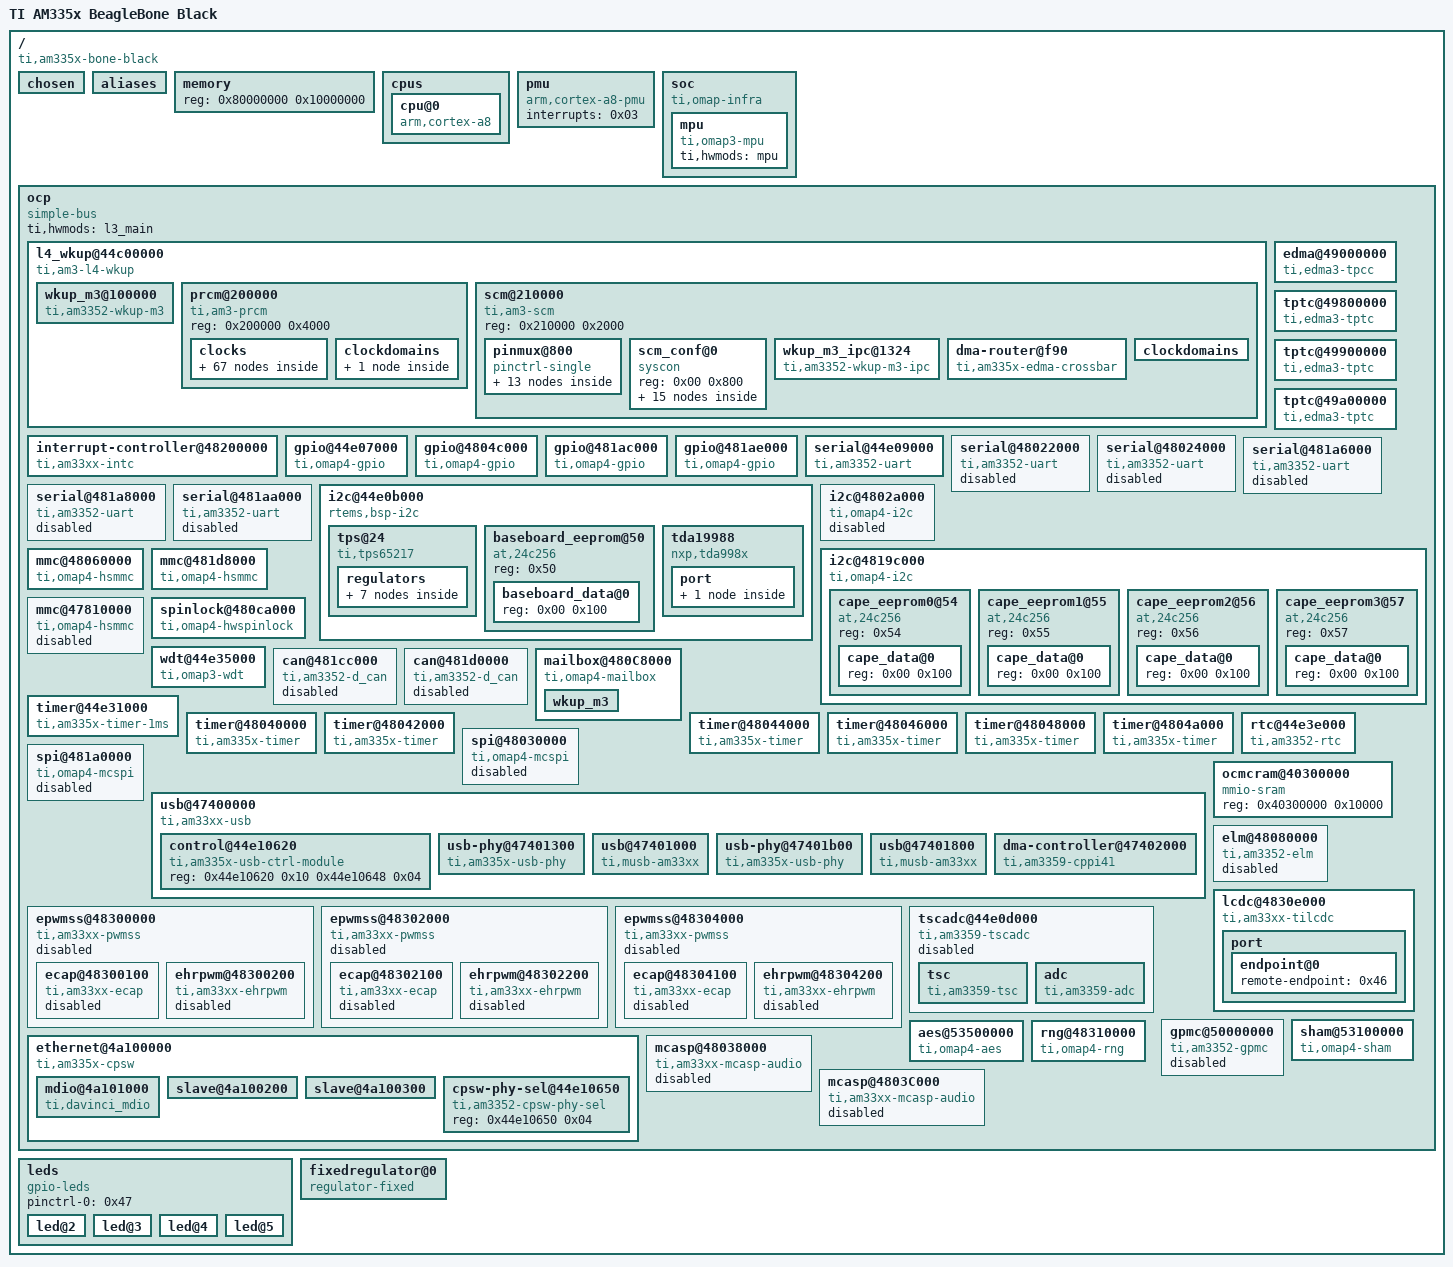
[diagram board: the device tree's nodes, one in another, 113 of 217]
/dts-v1/;

/ {
	#address-cells = < 0x01 >;
	#size-cells = < 0x01 >;
	compatible = "ti,am335x-bone-black\0ti,am335x-bone\0ti,am33xx";
	interrupt-parent = < 0x01 >;
	model = "TI AM335x BeagleBone Black";

	chosen {
	};

	aliases {
		i2c0 = "/ocp/i2c@44e0b000";
		i2c1 = "/ocp/i2c@4802a000";
		i2c2 = "/ocp/i2c@4819c000";
		serial0 = "/ocp/serial@44e09000";
		serial1 = "/ocp/serial@48022000";
		serial2 = "/ocp/serial@48024000";
		serial3 = "/ocp/serial@481a6000";
		serial4 = "/ocp/serial@481a8000";
		serial5 = "/ocp/serial@481aa000";
		d_can0 = "/ocp/can@481cc000";
		d_can1 = "/ocp/can@481d0000";
		usb0 = "/ocp/usb@47400000/usb@47401000";
		usb1 = "/ocp/usb@47400000/usb@47401800";
		phy0 = "/ocp/usb@47400000/usb-phy@47401300";
		phy1 = "/ocp/usb@47400000/usb-phy@47401b00";
		ethernet0 = "/ocp/ethernet@4a100000/slave@4a100200";
		ethernet1 = "/ocp/ethernet@4a100000/slave@4a100300";
	};

	memory {
		device_type = "memory";
		reg = < 0x80000000 0x10000000 >;
	};

	cpus {
		#address-cells = < 0x01 >;
		#size-cells = < 0x00 >;

		cpu@0 {
			compatible = "arm,cortex-a8";
			device_type = "cpu";
			reg = < 0x00 >;
			operating-points = < 0xafc80 0x139b88 0x927c0 0x12b128 0x7a120 0x112a88 0x43238 0x112a88 >;
			voltage-tolerance = < 0x02 >;
			clocks = < 0x02 >;
			clock-names = "cpu";
			clock-latency = < 0x493e0 >;
			cpu0-supply = < 0x03 >;
		};
	};

	pmu {
		compatible = "arm,cortex-a8-pmu";
		interrupts = < 0x03 >;
	};

	soc {
		compatible = "ti,omap-infra";

		mpu {
			compatible = "ti,omap3-mpu";
			ti,hwmods = "mpu";
		};
	};

	ocp {
		compatible = "simple-bus";
		#address-cells = < 0x01 >;
		#size-cells = < 0x01 >;
		ranges;
		ti,hwmods = "l3_main";

		l4_wkup@44c00000 {
			compatible = "ti,am3-l4-wkup\0simple-bus";
			#address-cells = < 0x01 >;
			#size-cells = < 0x01 >;
			ranges = < 0x00 0x44c00000 0x280000 >;
			linux,phandle = < 0x49 >;
			phandle = < 0x49 >;

			wkup_m3@100000 {
				compatible = "ti,am3352-wkup-m3";
				reg = < 0x100000 0x4000 0x180000 0x2000 >;
				reg-names = "umem\0dmem";
				ti,hwmods = "wkup_m3";
				ti,pm-firmware = "am335x-pm-firmware.elf";
				linux,phandle = < 0x26 >;
				phandle = < 0x26 >;
			};

			prcm@200000 {
				compatible = "ti,am3-prcm";
				reg = < 0x200000 0x4000 >;
				linux,phandle = < 0x4a >;
				phandle = < 0x4a >;

				clocks {
					#address-cells = < 0x01 >;
					#size-cells = < 0x00 >;
					linux,phandle = < 0x4b >;
					phandle = < 0x4b >;

					clk_32768_ck {
						#clock-cells = < 0x00 >;
						compatible = "fixed-clock";
						clock-frequency = < 0x8000 >;
						linux,phandle = < 0x14 >;
						phandle = < 0x14 >;
					};

					clk_rc32k_ck {
						#clock-cells = < 0x00 >;
						compatible = "fixed-clock";
						clock-frequency = < 0x7d00 >;
						linux,phandle = < 0x13 >;
						phandle = < 0x13 >;
					};

					virt_19200000_ck {
						#clock-cells = < 0x00 >;
						compatible = "fixed-clock";
						clock-frequency = < 0x124f800 >;
						linux,phandle = < 0x21 >;
						phandle = < 0x21 >;
					};

					virt_24000000_ck {
						#clock-cells = < 0x00 >;
						compatible = "fixed-clock";
						clock-frequency = < 0x16e3600 >;
						linux,phandle = < 0x22 >;
						phandle = < 0x22 >;
					};

					virt_25000000_ck {
						#clock-cells = < 0x00 >;
						compatible = "fixed-clock";
						clock-frequency = < 0x17d7840 >;
						linux,phandle = < 0x23 >;
						phandle = < 0x23 >;
					};

					virt_26000000_ck {
						#clock-cells = < 0x00 >;
						compatible = "fixed-clock";
						clock-frequency = < 0x18cba80 >;
						linux,phandle = < 0x24 >;
						phandle = < 0x24 >;
					};

					tclkin_ck {
						#clock-cells = < 0x00 >;
						compatible = "fixed-clock";
						clock-frequency = < 0xb71b00 >;
						linux,phandle = < 0x12 >;
						phandle = < 0x12 >;
					};

					dpll_core_ck {
						#clock-cells = < 0x00 >;
						compatible = "ti,am3-dpll-core-clock";
						clocks = < 0x04 0x04 >;
						reg = < 0x490 0x45c 0x468 >;
						linux,phandle = < 0x05 >;
						phandle = < 0x05 >;
					};

					dpll_core_x2_ck {
						#clock-cells = < 0x00 >;
						compatible = "ti,am3-dpll-x2-clock";
						clocks = < 0x05 >;
						linux,phandle = < 0x06 >;
						phandle = < 0x06 >;
					};

					dpll_core_m4_ck {
						#clock-cells = < 0x00 >;
						compatible = "ti,divider-clock";
						clocks = < 0x06 >;
						ti,max-div = < 0x1f >;
						reg = < 0x480 >;
						ti,index-starts-at-one;
						linux,phandle = < 0x0e >;
						phandle = < 0x0e >;
					};

					dpll_core_m5_ck {
						#clock-cells = < 0x00 >;
						compatible = "ti,divider-clock";
						clocks = < 0x06 >;
						ti,max-div = < 0x1f >;
						reg = < 0x484 >;
						ti,index-starts-at-one;
						linux,phandle = < 0x16 >;
						phandle = < 0x16 >;
					};

					dpll_core_m6_ck {
						#clock-cells = < 0x00 >;
						compatible = "ti,divider-clock";
						clocks = < 0x06 >;
						ti,max-div = < 0x1f >;
						reg = < 0x4d8 >;
						ti,index-starts-at-one;
						linux,phandle = < 0x4c >;
						phandle = < 0x4c >;
					};

					dpll_mpu_ck {
						#clock-cells = < 0x00 >;
						compatible = "ti,am3-dpll-clock";
						clocks = < 0x04 0x04 >;
						reg = < 0x488 0x420 0x42c >;
						linux,phandle = < 0x02 >;
						phandle = < 0x02 >;
					};

					dpll_mpu_m2_ck {
						#clock-cells = < 0x00 >;
						compatible = "ti,divider-clock";
						clocks = < 0x02 >;
						ti,max-div = < 0x1f >;
						reg = < 0x4a8 >;
						ti,index-starts-at-one;
						linux,phandle = < 0x4d >;
						phandle = < 0x4d >;
					};

					dpll_ddr_ck {
						#clock-cells = < 0x00 >;
						compatible = "ti,am3-dpll-no-gate-clock";
						clocks = < 0x04 0x04 >;
						reg = < 0x494 0x434 0x440 >;
						linux,phandle = < 0x07 >;
						phandle = < 0x07 >;
					};

					dpll_ddr_m2_ck {
						#clock-cells = < 0x00 >;
						compatible = "ti,divider-clock";
						clocks = < 0x07 >;
						ti,max-div = < 0x1f >;
						reg = < 0x4a0 >;
						ti,index-starts-at-one;
						linux,phandle = < 0x08 >;
						phandle = < 0x08 >;
					};

					dpll_ddr_m2_div2_ck {
						#clock-cells = < 0x00 >;
						compatible = "fixed-factor-clock";
						clocks = < 0x08 >;
						clock-mult = < 0x01 >;
						clock-div = < 0x02 >;
						linux,phandle = < 0x4e >;
						phandle = < 0x4e >;
					};

					dpll_disp_ck {
						#clock-cells = < 0x00 >;
						compatible = "ti,am3-dpll-no-gate-clock";
						clocks = < 0x04 0x04 >;
						reg = < 0x498 0x448 0x454 >;
						linux,phandle = < 0x09 >;
						phandle = < 0x09 >;
					};

					dpll_disp_m2_ck {
						#clock-cells = < 0x00 >;
						compatible = "ti,divider-clock";
						clocks = < 0x09 >;
						ti,max-div = < 0x1f >;
						reg = < 0x4a4 >;
						ti,index-starts-at-one;
						ti,set-rate-parent;
						linux,phandle = < 0x10 >;
						phandle = < 0x10 >;
					};

					dpll_per_ck {
						#clock-cells = < 0x00 >;
						compatible = "ti,am3-dpll-no-gate-j-type-clock";
						clocks = < 0x04 0x04 >;
						reg = < 0x48c 0x470 0x49c >;
						linux,phandle = < 0x0a >;
						phandle = < 0x0a >;
					};

					dpll_per_m2_ck {
						#clock-cells = < 0x00 >;
						compatible = "ti,divider-clock";
						clocks = < 0x0a >;
						ti,max-div = < 0x1f >;
						reg = < 0x4ac >;
						ti,index-starts-at-one;
						linux,phandle = < 0x0b >;
						phandle = < 0x0b >;
					};

					dpll_per_m2_div4_wkupdm_ck {
						#clock-cells = < 0x00 >;
						compatible = "fixed-factor-clock";
						clocks = < 0x0b >;
						clock-mult = < 0x01 >;
						clock-div = < 0x04 >;
						linux,phandle = < 0x4f >;
						phandle = < 0x4f >;
					};

					dpll_per_m2_div4_ck {
						#clock-cells = < 0x00 >;
						compatible = "fixed-factor-clock";
						clocks = < 0x0b >;
						clock-mult = < 0x01 >;
						clock-div = < 0x04 >;
						linux,phandle = < 0x50 >;
						phandle = < 0x50 >;
					};

					cefuse_fck {
						#clock-cells = < 0x00 >;
						compatible = "ti,gate-clock";
						clocks = < 0x04 >;
						ti,bit-shift = < 0x01 >;
						reg = < 0xa20 >;
						linux,phandle = < 0x51 >;
						phandle = < 0x51 >;
					};

					clk_24mhz {
						#clock-cells = < 0x00 >;
						compatible = "fixed-factor-clock";
						clocks = < 0x0b >;
						clock-mult = < 0x01 >;
						clock-div = < 0x08 >;
						linux,phandle = < 0x0c >;
						phandle = < 0x0c >;
					};

					clkdiv32k_ck {
						#clock-cells = < 0x00 >;
						compatible = "fixed-factor-clock";
						clocks = < 0x0c >;
						clock-mult = < 0x01 >;
						clock-div = < 0x2dc >;
						linux,phandle = < 0x0d >;
						phandle = < 0x0d >;
					};

					clkdiv32k_ick {
						#clock-cells = < 0x00 >;
						compatible = "ti,gate-clock";
						clocks = < 0x0d >;
						ti,bit-shift = < 0x01 >;
						reg = < 0x14c >;
						linux,phandle = < 0x11 >;
						phandle = < 0x11 >;
					};

					l3_gclk {
						#clock-cells = < 0x00 >;
						compatible = "fixed-factor-clock";
						clocks = < 0x0e >;
						clock-mult = < 0x01 >;
						clock-div = < 0x01 >;
						linux,phandle = < 0x0f >;
						phandle = < 0x0f >;
					};

					pruss_ocp_gclk {
						#clock-cells = < 0x00 >;
						compatible = "ti,mux-clock";
						clocks = < 0x0f 0x10 >;
						reg = < 0x530 >;
						linux,phandle = < 0x52 >;
						phandle = < 0x52 >;
					};

					mmu_fck {
						#clock-cells = < 0x00 >;
						compatible = "ti,gate-clock";
						clocks = < 0x0e >;
						ti,bit-shift = < 0x01 >;
						reg = < 0x914 >;
						linux,phandle = < 0x53 >;
						phandle = < 0x53 >;
					};

					timer1_fck {
						#clock-cells = < 0x00 >;
						compatible = "ti,mux-clock";
						clocks = < 0x04 0x11 0x12 0x13 0x14 >;
						reg = < 0x528 >;
						linux,phandle = < 0x54 >;
						phandle = < 0x54 >;
					};

					timer2_fck {
						#clock-cells = < 0x00 >;
						compatible = "ti,mux-clock";
						clocks = < 0x12 0x04 0x11 >;
						reg = < 0x508 >;
						linux,phandle = < 0x55 >;
						phandle = < 0x55 >;
					};

					timer3_fck {
						#clock-cells = < 0x00 >;
						compatible = "ti,mux-clock";
						clocks = < 0x12 0x04 0x11 >;
						reg = < 0x50c >;
						linux,phandle = < 0x56 >;
						phandle = < 0x56 >;
					};

					timer4_fck {
						#clock-cells = < 0x00 >;
						compatible = "ti,mux-clock";
						clocks = < 0x12 0x04 0x11 >;
						reg = < 0x510 >;
						linux,phandle = < 0x57 >;
						phandle = < 0x57 >;
					};

					timer5_fck {
						#clock-cells = < 0x00 >;
						compatible = "ti,mux-clock";
						clocks = < 0x12 0x04 0x11 >;
						reg = < 0x518 >;
						linux,phandle = < 0x58 >;
						phandle = < 0x58 >;
					};

					timer6_fck {
						#clock-cells = < 0x00 >;
						compatible = "ti,mux-clock";
						clocks = < 0x12 0x04 0x11 >;
						reg = < 0x51c >;
						linux,phandle = < 0x59 >;
						phandle = < 0x59 >;
					};

					timer7_fck {
						#clock-cells = < 0x00 >;
						compatible = "ti,mux-clock";
						clocks = < 0x12 0x04 0x11 >;
						reg = < 0x504 >;
						linux,phandle = < 0x5a >;
						phandle = < 0x5a >;
					};

					usbotg_fck {
						#clock-cells = < 0x00 >;
						compatible = "ti,gate-clock";
						clocks = < 0x0a >;
						ti,bit-shift = < 0x08 >;
						reg = < 0x47c >;
						linux,phandle = < 0x5b >;
						phandle = < 0x5b >;
					};

					dpll_core_m4_div2_ck {
						#clock-cells = < 0x00 >;
						compatible = "fixed-factor-clock";
						clocks = < 0x0e >;
						clock-mult = < 0x01 >;
						clock-div = < 0x02 >;
						linux,phandle = < 0x15 >;
						phandle = < 0x15 >;
					};

					ieee5000_fck {
						#clock-cells = < 0x00 >;
						compatible = "ti,gate-clock";
						clocks = < 0x15 >;
						ti,bit-shift = < 0x01 >;
						reg = < 0xe4 >;
						linux,phandle = < 0x5c >;
						phandle = < 0x5c >;
					};

					wdt1_fck {
						#clock-cells = < 0x00 >;
						compatible = "ti,mux-clock";
						clocks = < 0x13 0x11 >;
						reg = < 0x538 >;
						linux,phandle = < 0x5d >;
						phandle = < 0x5d >;
					};

					l4_rtc_gclk {
						#clock-cells = < 0x00 >;
						compatible = "fixed-factor-clock";
						clocks = < 0x0e >;
						clock-mult = < 0x01 >;
						clock-div = < 0x02 >;
						linux,phandle = < 0x5e >;
						phandle = < 0x5e >;
					};

					l4hs_gclk {
						#clock-cells = < 0x00 >;
						compatible = "fixed-factor-clock";
						clocks = < 0x0e >;
						clock-mult = < 0x01 >;
						clock-div = < 0x01 >;
						linux,phandle = < 0x5f >;
						phandle = < 0x5f >;
					};

					l3s_gclk {
						#clock-cells = < 0x00 >;
						compatible = "fixed-factor-clock";
						clocks = < 0x15 >;
						clock-mult = < 0x01 >;
						clock-div = < 0x01 >;
						linux,phandle = < 0x60 >;
						phandle = < 0x60 >;
					};

					l4fw_gclk {
						#clock-cells = < 0x00 >;
						compatible = "fixed-factor-clock";
						clocks = < 0x15 >;
						clock-mult = < 0x01 >;
						clock-div = < 0x01 >;
						linux,phandle = < 0x61 >;
						phandle = < 0x61 >;
					};

					l4ls_gclk {
						#clock-cells = < 0x00 >;
						compatible = "fixed-factor-clock";
						clocks = < 0x15 >;
						clock-mult = < 0x01 >;
						clock-div = < 0x01 >;
						linux,phandle = < 0x25 >;
						phandle = < 0x25 >;
					};

					sysclk_div_ck {
						#clock-cells = < 0x00 >;
						compatible = "fixed-factor-clock";
						clocks = < 0x0e >;
						clock-mult = < 0x01 >;
						clock-div = < 0x01 >;
						linux,phandle = < 0x62 >;
						phandle = < 0x62 >;
					};

					cpsw_125mhz_gclk {
						#clock-cells = < 0x00 >;
						compatible = "fixed-factor-clock";
						clocks = < 0x16 >;
						clock-mult = < 0x01 >;
						clock-div = < 0x02 >;
						linux,phandle = < 0x3f >;
						phandle = < 0x3f >;
					};

					cpsw_cpts_rft_clk {
						#clock-cells = < 0x00 >;
						compatible = "ti,mux-clock";
						clocks = < 0x16 0x0e >;
						reg = < 0x520 >;
						linux,phandle = < 0x40 >;
						phandle = < 0x40 >;
					};

					gpio0_dbclk_mux_ck {
						#clock-cells = < 0x00 >;
						compatible = "ti,mux-clock";
						clocks = < 0x13 0x14 0x11 >;
						reg = < 0x53c >;
						linux,phandle = < 0x17 >;
						phandle = < 0x17 >;
					};

					gpio0_dbclk {
						#clock-cells = < 0x00 >;
						compatible = "ti,gate-clock";
						clocks = < 0x17 >;
						ti,bit-shift = < 0x12 >;
						reg = < 0x408 >;
						linux,phandle = < 0x63 >;
						phandle = < 0x63 >;
					};

					gpio1_dbclk {
						#clock-cells = < 0x00 >;
						compatible = "ti,gate-clock";
						clocks = < 0x11 >;
						ti,bit-shift = < 0x12 >;
						reg = < 0xac >;
						linux,phandle = < 0x64 >;
						phandle = < 0x64 >;
					};

					gpio2_dbclk {
						#clock-cells = < 0x00 >;
						compatible = "ti,gate-clock";
						clocks = < 0x11 >;
						ti,bit-shift = < 0x12 >;
						reg = < 0xb0 >;
						linux,phandle = < 0x65 >;
						phandle = < 0x65 >;
					};

					gpio3_dbclk {
						#clock-cells = < 0x00 >;
						compatible = "ti,gate-clock";
						clocks = < 0x11 >;
						ti,bit-shift = < 0x12 >;
						reg = < 0xb4 >;
						linux,phandle = < 0x66 >;
						phandle = < 0x66 >;
					};

					lcd_gclk {
						#clock-cells = < 0x00 >;
						compatible = "ti,mux-clock";
						clocks = < 0x10 0x16 0x0b >;
						reg = < 0x534 >;
						ti,set-rate-parent;
						linux,phandle = < 0x19 >;
						phandle = < 0x19 >;
					};

					mmc_clk {
						#clock-cells = < 0x00 >;
						compatible = "fixed-factor-clock";
						clocks = < 0x0b >;
						clock-mult = < 0x01 >;
						clock-div = < 0x02 >;
						linux,phandle = < 0x67 >;
						phandle = < 0x67 >;
					};

					gfx_fclk_clksel_ck {
						#clock-cells = < 0x00 >;
						compatible = "ti,mux-clock";
						clocks = < 0x0e 0x0b >;
						ti,bit-shift = < 0x01 >;
						reg = < 0x52c >;
						linux,phandle = < 0x18 >;
						phandle = < 0x18 >;
					};

					gfx_fck_div_ck {
						#clock-cells = < 0x00 >;
						compatible = "ti,divider-clock";
						clocks = < 0x18 >;
						reg = < 0x52c >;
						ti,max-div = < 0x02 >;
						linux,phandle = < 0x68 >;
						phandle = < 0x68 >;
					};

					sysclkout_pre_ck {
						#clock-cells = < 0x00 >;
						compatible = "ti,mux-clock";
						clocks = < 0x14 0x0f 0x08 0x0b 0x19 >;
						reg = < 0x700 >;
						linux,phandle = < 0x1a >;
						phandle = < 0x1a >;
					};

					clkout2_div_ck {
						#clock-cells = < 0x00 >;
						compatible = "ti,divider-clock";
						clocks = < 0x1a >;
						ti,bit-shift = < 0x03 >;
						ti,max-div = < 0x08 >;
						reg = < 0x700 >;
						linux,phandle = < 0x1f >;
						phandle = < 0x1f >;
					};

					dbg_sysclk_ck {
						#clock-cells = < 0x00 >;
						compatible = "ti,gate-clock";
						clocks = < 0x04 >;
						ti,bit-shift = < 0x13 >;
						reg = < 0x414 >;
						linux,phandle = < 0x1b >;
						phandle = < 0x1b >;
					};

					dbg_clka_ck {
						#clock-cells = < 0x00 >;
						compatible = "ti,gate-clock";
						clocks = < 0x0e >;
						ti,bit-shift = < 0x1e >;
						reg = < 0x414 >;
						linux,phandle = < 0x1c >;
						phandle = < 0x1c >;
					};

					stm_pmd_clock_mux_ck {
						#clock-cells = < 0x00 >;
						compatible = "ti,mux-clock";
						clocks = < 0x1b 0x1c >;
						ti,bit-shift = < 0x16 >;
						reg = < 0x414 >;
						linux,phandle = < 0x1d >;
						phandle = < 0x1d >;
					};

					trace_pmd_clk_mux_ck {
						#clock-cells = < 0x00 >;
						compatible = "ti,mux-clock";
						clocks = < 0x1b 0x1c >;
						ti,bit-shift = < 0x14 >;
						reg = < 0x414 >;
						linux,phandle = < 0x1e >;
						phandle = < 0x1e >;
					};

					stm_clk_div_ck {
						#clock-cells = < 0x00 >;
						compatible = "ti,divider-clock";
						clocks = < 0x1d >;
						ti,bit-shift = < 0x1b >;
						ti,max-div = < 0x40 >;
						reg = < 0x414 >;
						ti,index-power-of-two;
						linux,phandle = < 0x69 >;
						phandle = < 0x69 >;
					};

					trace_clk_div_ck {
						#clock-cells = < 0x00 >;
						compatible = "ti,divider-clock";
						clocks = < 0x1e >;
						ti,bit-shift = < 0x18 >;
						ti,max-div = < 0x40 >;
						reg = < 0x414 >;
						ti,index-power-of-two;
						linux,phandle = < 0x6a >;
						phandle = < 0x6a >;
					};

					clkout2_ck {
						#clock-cells = < 0x00 >;
						compatible = "ti,gate-clock";
						clocks = < 0x1f >;
						ti,bit-shift = < 0x07 >;
						reg = < 0x700 >;
						linux,phandle = < 0x6b >;
						phandle = < 0x6b >;
					};
				};

				clockdomains {
					linux,phandle = < 0x6c >;
					phandle = < 0x6c >;

					clk_24mhz_clkdm {
						compatible = "ti,clockdomain";
						clocks = < 0x11 >;
						linux,phandle = < 0x6d >;
						phandle = < 0x6d >;
					};
				};
			};

			scm@210000 {
				compatible = "ti,am3-scm\0simple-bus";
				reg = < 0x210000 0x2000 >;
				#address-cells = < 0x01 >;
				#size-cells = < 0x01 >;
				ranges = < 0x00 0x210000 0x2000 >;
				linux,phandle = < 0x6e >;
				phandle = < 0x6e >;

				pinmux@800 {
					compatible = "pinctrl-single";
					reg = < 0x800 0x238 >;
					#address-cells = < 0x01 >;
					#size-cells = < 0x00 >;
					pinctrl-single,register-width = < 0x20 >;
					pinctrl-single,function-mask = < 0x7f >;
					pinctrl-names = "default";
					pinctrl-0 = < 0x20 >;
					linux,phandle = < 0x6f >;
					phandle = < 0x6f >;

					user_leds_s0 {
						pinctrl-single,pins = < 0x54 0x07 0x58 0x17 0x5c 0x07 0x60 0x17 >;
						linux,phandle = < 0x47 >;
						phandle = < 0x47 >;
					};

					pinmux_i2c0_pins {
						pinctrl-single,pins = < 0x188 0x30 0x18c 0x30 >;
						linux,phandle = < 0x2e >;
						phandle = < 0x2e >;
					};

					pinmux_i2c2_pins {
						pinctrl-single,pins = < 0x178 0x33 0x17c 0x33 >;
						linux,phandle = < 0x32 >;
						phandle = < 0x32 >;
					};

					pinmux_uart0_pins {
						pinctrl-single,pins = < 0x170 0x30 0x174 0x00 >;
						linux,phandle = < 0x2d >;
						phandle = < 0x2d >;
					};

					pinmux_clkout2_pin {
						pinctrl-single,pins = < 0x1b4 0x03 >;
						linux,phandle = < 0x20 >;
						phandle = < 0x20 >;
					};

					cpsw_default {
						pinctrl-single,pins = < 0x110 0x30 0x114 0x00 0x118 0x30 0x11c 0x00 0x120 0x00 0x124 0x00 0x128 0x00 0x12c 0x30 0x130 0x30 0x134 0x30 0x138 0x30 0x13c 0x30 0x140 0x30 >;
						linux,phandle = < 0x41 >;
						phandle = < 0x41 >;
					};

					cpsw_sleep {
						pinctrl-single,pins = < 0x110 0x27 0x114 0x27 0x118 0x27 0x11c 0x27 0x120 0x27 0x124 0x27 0x128 0x27 0x12c 0x27 0x130 0x27 0x134 0x27 0x138 0x27 0x13c 0x27 0x140 0x27 >;
						linux,phandle = < 0x42 >;
						phandle = < 0x42 >;
					};

					davinci_mdio_default {
						pinctrl-single,pins = < 0x148 0x30 0x14c 0x10 >;
						linux,phandle = < 0x43 >;
						phandle = < 0x43 >;
					};

					davinci_mdio_sleep {
						pinctrl-single,pins = < 0x148 0x27 0x14c 0x27 >;
						linux,phandle = < 0x44 >;
						phandle = < 0x44 >;
					};

					pinmux_mmc1_pins {
						pinctrl-single,pins = < 0x160 0x2f >;
						linux,phandle = < 0x34 >;
						phandle = < 0x34 >;
					};

					pinmux_emmc_pins {
						pinctrl-single,pins = < 0x80 0x32 0x84 0x32 0x00 0x31 0x04 0x31 0x08 0x31 0x0c 0x31 0x10 0x31 0x14 0x31 0x18 0x31 0x1c 0x31 >;
						linux,phandle = < 0x37 >;
						phandle = < 0x37 >;
					};

					nxp_hdmi_bonelt_pins {
						pinctrl-single,pins = < 0x1b0 0x03 0xa0 0x08 0xa4 0x08 0xa8 0x08 0xac 0x08 0xb0 0x08 0xb4 0x08 0xb8 0x08 0xbc 0x08 0xc0 0x08 0xc4 0x08 0xc8 0x08 0xcc 0x08 0xd0 0x08 0xd4 0x08 0xd8 0x08 0xdc 0x08 0xe0 0x00 0xe4 0x00 0xe8 0x00 0xec 0x00 >;
						linux,phandle = < 0x2f >;
						phandle = < 0x2f >;
					};

					nxp_hdmi_bonelt_off_pins {
						pinctrl-single,pins = < 0x1b0 0x03 >;
						linux,phandle = < 0x30 >;
						phandle = < 0x30 >;
					};
				};

				scm_conf@0 {
					compatible = "syscon";
					reg = < 0x00 0x800 >;
					#address-cells = < 0x01 >;
					#size-cells = < 0x01 >;
					linux,phandle = < 0x39 >;
					phandle = < 0x39 >;

					clocks {
						#address-cells = < 0x01 >;
						#size-cells = < 0x00 >;
						linux,phandle = < 0x70 >;
						phandle = < 0x70 >;

						sys_clkin_ck {
							#clock-cells = < 0x00 >;
							compatible = "ti,mux-clock";
							clocks = < 0x21 0x22 0x23 0x24 >;
							ti,bit-shift = < 0x16 >;
							reg = < 0x40 >;
							linux,phandle = < 0x04 >;
							phandle = < 0x04 >;
						};

						adc_tsc_fck {
							#clock-cells = < 0x00 >;
							compatible = "fixed-factor-clock";
							clocks = < 0x04 >;
							clock-mult = < 0x01 >;
							clock-div = < 0x01 >;
							linux,phandle = < 0x71 >;
							phandle = < 0x71 >;
						};

						dcan0_fck {
							#clock-cells = < 0x00 >;
							compatible = "fixed-factor-clock";
							clocks = < 0x04 >;
							clock-mult = < 0x01 >;
							clock-div = < 0x01 >;
							linux,phandle = < 0x38 >;
							phandle = < 0x38 >;
						};

						dcan1_fck {
							#clock-cells = < 0x00 >;
							compatible = "fixed-factor-clock";
							clocks = < 0x04 >;
							clock-mult = < 0x01 >;
							clock-div = < 0x01 >;
							linux,phandle = < 0x3a >;
							phandle = < 0x3a >;
						};

						mcasp0_fck {
							#clock-cells = < 0x00 >;
							compatible = "fixed-factor-clock";
							clocks = < 0x04 >;
							clock-mult = < 0x01 >;
							clock-div = < 0x01 >;
							linux,phandle = < 0x72 >;
							phandle = < 0x72 >;
						};

						mcasp1_fck {
							#clock-cells = < 0x00 >;
							compatible = "fixed-factor-clock";
							clocks = < 0x04 >;
							clock-mult = < 0x01 >;
							clock-div = < 0x01 >;
							linux,phandle = < 0x73 >;
							phandle = < 0x73 >;
						};

						smartreflex0_fck {
							#clock-cells = < 0x00 >;
							compatible = "fixed-factor-clock";
							clocks = < 0x04 >;
							clock-mult = < 0x01 >;
							clock-div = < 0x01 >;
							linux,phandle = < 0x74 >;
							phandle = < 0x74 >;
						};

						smartreflex1_fck {
							#clock-cells = < 0x00 >;
							compatible = "fixed-factor-clock";
							clocks = < 0x04 >;
							clock-mult = < 0x01 >;
							clock-div = < 0x01 >;
							linux,phandle = < 0x75 >;
							phandle = < 0x75 >;
						};

						sha0_fck {
							#clock-cells = < 0x00 >;
							compatible = "fixed-factor-clock";
							clocks = < 0x04 >;
							clock-mult = < 0x01 >;
							clock-div = < 0x01 >;
							linux,phandle = < 0x76 >;
							phandle = < 0x76 >;
						};

						aes0_fck {
							#clock-cells = < 0x00 >;
							compatible = "fixed-factor-clock";
							clocks = < 0x04 >;
							clock-mult = < 0x01 >;
							clock-div = < 0x01 >;
							linux,phandle = < 0x77 >;
							phandle = < 0x77 >;
						};

						rng_fck {
							#clock-cells = < 0x00 >;
							compatible = "fixed-factor-clock";
							clocks = < 0x04 >;
							clock-mult = < 0x01 >;
							clock-div = < 0x01 >;
							linux,phandle = < 0x78 >;
							phandle = < 0x78 >;
						};

						ehrpwm0_tbclk@44e10664 {
							#clock-cells = < 0x00 >;
							compatible = "ti,gate-clock";
							clocks = < 0x25 >;
							ti,bit-shift = < 0x00 >;
							reg = < 0x664 >;
							linux,phandle = < 0x79 >;
							phandle = < 0x79 >;
						};

						ehrpwm1_tbclk@44e10664 {
							#clock-cells = < 0x00 >;
							compatible = "ti,gate-clock";
							clocks = < 0x25 >;
							ti,bit-shift = < 0x01 >;
							reg = < 0x664 >;
							linux,phandle = < 0x7a >;
							phandle = < 0x7a >;
						};

						ehrpwm2_tbclk@44e10664 {
							#clock-cells = < 0x00 >;
							compatible = "ti,gate-clock";
							clocks = < 0x25 >;
							ti,bit-shift = < 0x02 >;
							reg = < 0x664 >;
							linux,phandle = < 0x7b >;
							phandle = < 0x7b >;
						};
					};
				};

				wkup_m3_ipc@1324 {
					compatible = "ti,am3352-wkup-m3-ipc";
					reg = < 0x1324 0x24 >;
					interrupts = < 0x4e >;
					ti,rproc = < 0x26 >;
					mboxes = < 0x27 0x28 >;
					linux,phandle = < 0x7c >;
					phandle = < 0x7c >;
				};

				dma-router@f90 {
					compatible = "ti,am335x-edma-crossbar";
					reg = < 0xf90 0x40 >;
					#dma-cells = < 0x03 >;
					dma-requests = < 0x20 >;
					dma-masters = < 0x29 >;
					linux,phandle = < 0x33 >;
					phandle = < 0x33 >;
				};

				clockdomains {
					linux,phandle = < 0x7d >;
					phandle = < 0x7d >;
				};
			};
		};

		interrupt-controller@48200000 {
			compatible = "ti,am33xx-intc";
			interrupt-controller;
			#interrupt-cells = < 0x01 >;
			reg = < 0x48200000 0x1000 >;
			linux,phandle = < 0x01 >;
			phandle = < 0x01 >;
		};

		edma@49000000 {
			compatible = "ti,edma3-tpcc";
			ti,hwmods = "tpcc";
			reg = < 0x49000000 0x10000 >;
			reg-names = "edma3_cc";
			interrupts = < 0x0c 0x0d 0x0e >;
			interrupt-names = "edma3_ccint\0emda3_mperr\0edma3_ccerrint";
			dma-requests = < 0x40 >;
			#dma-cells = < 0x02 >;
			ti,tptcs = < 0x2a 0x07 0x2b 0x05 0x2c 0x00 >;
			ti,edma-memcpy-channels = < 0x14 0x15 >;
			linux,phandle = < 0x29 >;
			phandle = < 0x29 >;
		};

		tptc@49800000 {
			compatible = "ti,edma3-tptc";
			ti,hwmods = "tptc0";
			reg = < 0x49800000 0x100000 >;
			interrupts = < 0x70 >;
			interrupt-names = "edma3_tcerrint";
			linux,phandle = < 0x2a >;
			phandle = < 0x2a >;
		};

		tptc@49900000 {
			compatible = "ti,edma3-tptc";
			ti,hwmods = "tptc1";
			reg = < 0x49900000 0x100000 >;
			interrupts = < 0x71 >;
			interrupt-names = "edma3_tcerrint";
			linux,phandle = < 0x2b >;
			phandle = < 0x2b >;
		};

		tptc@49a00000 {
			compatible = "ti,edma3-tptc";
			ti,hwmods = "tptc2";
			reg = < 0x49a00000 0x100000 >;
			interrupts = < 0x72 >;
			interrupt-names = "edma3_tcerrint";
			linux,phandle = < 0x2c >;
			phandle = < 0x2c >;
		};

		gpio@44e07000 {
			compatible = "ti,omap4-gpio";
			ti,hwmods = "gpio1";
			gpio-controller;
			#gpio-cells = < 0x02 >;
			interrupt-controller;
			#interrupt-cells = < 0x02 >;
			reg = < 0x44e07000 0x1000 >;
			interrupts = < 0x60 >;
			linux,phandle = < 0x35 >;
			phandle = < 0x35 >;
		};

		gpio@4804c000 {
			compatible = "ti,omap4-gpio";
			ti,hwmods = "gpio2";
			gpio-controller;
			#gpio-cells = < 0x02 >;
			interrupt-controller;
			#interrupt-cells = < 0x02 >;
			reg = < 0x4804c000 0x1000 >;
			interrupts = < 0x62 >;
			linux,phandle = < 0x48 >;
			phandle = < 0x48 >;
		};

		gpio@481ac000 {
			compatible = "ti,omap4-gpio";
			ti,hwmods = "gpio3";
			gpio-controller;
			#gpio-cells = < 0x02 >;
			interrupt-controller;
			#interrupt-cells = < 0x02 >;
			reg = < 0x481ac000 0x1000 >;
			interrupts = < 0x20 >;
			linux,phandle = < 0x7e >;
			phandle = < 0x7e >;
		};

		gpio@481ae000 {
			compatible = "ti,omap4-gpio";
			ti,hwmods = "gpio4";
			gpio-controller;
			#gpio-cells = < 0x02 >;
			interrupt-controller;
			#interrupt-cells = < 0x02 >;
			reg = < 0x481ae000 0x1000 >;
			interrupts = < 0x3e >;
			linux,phandle = < 0x7f >;
			phandle = < 0x7f >;
		};

		serial@44e09000 {
			compatible = "ti,am3352-uart\0ti,omap3-uart";
			ti,hwmods = "uart1";
			clock-frequency = < 0x2dc6c00 >;
			reg = < 0x44e09000 0x2000 >;
			interrupts = < 0x48 >;
			status = "okay";
			dmas = < 0x29 0x1a 0x00 0x29 0x1b 0x00 >;
			dma-names = "tx\0rx";
			pinctrl-names = "default";
			pinctrl-0 = < 0x2d >;
			linux,phandle = < 0x80 >;
			phandle = < 0x80 >;
		};

		serial@48022000 {
			compatible = "ti,am3352-uart\0ti,omap3-uart";
			ti,hwmods = "uart2";
			clock-frequency = < 0x2dc6c00 >;
			reg = < 0x48022000 0x2000 >;
			interrupts = < 0x49 >;
			status = "disabled";
			dmas = < 0x29 0x1c 0x00 0x29 0x1d 0x00 >;
			dma-names = "tx\0rx";
			linux,phandle = < 0x81 >;
			phandle = < 0x81 >;
		};

		serial@48024000 {
			compatible = "ti,am3352-uart\0ti,omap3-uart";
			ti,hwmods = "uart3";
			clock-frequency = < 0x2dc6c00 >;
			reg = < 0x48024000 0x2000 >;
			interrupts = < 0x4a >;
			status = "disabled";
			dmas = < 0x29 0x1e 0x00 0x29 0x1f 0x00 >;
			dma-names = "tx\0rx";
			linux,phandle = < 0x82 >;
			phandle = < 0x82 >;
		};

		serial@481a6000 {
			compatible = "ti,am3352-uart\0ti,omap3-uart";
			ti,hwmods = "uart4";
			clock-frequency = < 0x2dc6c00 >;
			reg = < 0x481a6000 0x2000 >;
			interrupts = < 0x2c >;
			status = "disabled";
			linux,phandle = < 0x83 >;
			phandle = < 0x83 >;
		};

		serial@481a8000 {
			compatible = "ti,am3352-uart\0ti,omap3-uart";
			ti,hwmods = "uart5";
			clock-frequency = < 0x2dc6c00 >;
			reg = < 0x481a8000 0x2000 >;
			interrupts = < 0x2d >;
			status = "disabled";
			linux,phandle = < 0x84 >;
			phandle = < 0x84 >;
		};

		serial@481aa000 {
			compatible = "ti,am3352-uart\0ti,omap3-uart";
			ti,hwmods = "uart6";
			clock-frequency = < 0x2dc6c00 >;
			reg = < 0x481aa000 0x2000 >;
			interrupts = < 0x2e >;
			status = "disabled";
			linux,phandle = < 0x85 >;
			phandle = < 0x85 >;
		};

		i2c@44e0b000 {
			rtems,i2c-path = "/dev/i2c-0";
			compatible = "rtems,bsp-i2c\0ti,omap4-i2c";
			#address-cells = < 0x01 >;
			#size-cells = < 0x00 >;
			ti,hwmods = "i2c1";
			reg = < 0x44e0b000 0x1000 >;
			interrupts = < 0x46 >;
			status = "okay";
			pinctrl-names = "default";
			pinctrl-0 = < 0x2e >;
			clock-frequency = < 0x61a80 >;
			linux,phandle = < 0x86 >;
			phandle = < 0x86 >;

			tps@24 {
				reg = < 0x24 >;
				compatible = "ti,tps65217";
				ti,pmic-shutdown-controller;
				linux,phandle = < 0x87 >;
				phandle = < 0x87 >;

				regulators {
					#address-cells = < 0x01 >;
					#size-cells = < 0x00 >;

					regulator@0 {
						reg = < 0x00 >;
						regulator-name = "vdds_dpr";
						regulator-always-on;
						linux,phandle = < 0x88 >;
						phandle = < 0x88 >;
					};

					regulator@1 {
						reg = < 0x01 >;
						regulator-name = "vdd_mpu";
						regulator-min-microvolt = < 0xe1d48 >;
						regulator-max-microvolt = < 0x1437c8 >;
						regulator-boot-on;
						regulator-always-on;
						linux,phandle = < 0x03 >;
						phandle = < 0x03 >;
					};

					regulator@2 {
						reg = < 0x02 >;
						regulator-name = "vdd_core";
						regulator-min-microvolt = < 0xe1d48 >;
						regulator-max-microvolt = < 0x118c30 >;
						regulator-boot-on;
						regulator-always-on;
						linux,phandle = < 0x89 >;
						phandle = < 0x89 >;
					};

					regulator@3 {
						reg = < 0x03 >;
						regulator-name = "vio,vrtc,vdds";
						regulator-always-on;
						linux,phandle = < 0x8a >;
						phandle = < 0x8a >;
					};

					regulator@4 {
						reg = < 0x04 >;
						regulator-name = "vdd_3v3aux";
						regulator-always-on;
						linux,phandle = < 0x8b >;
						phandle = < 0x8b >;
					};

					regulator@5 {
						reg = < 0x05 >;
						regulator-name = "vdd_1v8";
						regulator-always-on;
						regulator-min-microvolt = < 0x1b7740 >;
						regulator-max-microvolt = < 0x1b7740 >;
						linux,phandle = < 0x8c >;
						phandle = < 0x8c >;
					};

					regulator@6 {
						reg = < 0x06 >;
						regulator-name = "vdd_3v3a";
						regulator-always-on;
						linux,phandle = < 0x8d >;
						phandle = < 0x8d >;
					};
				};
			};

			baseboard_eeprom@50 {
				compatible = "at,24c256";
				reg = < 0x50 >;
				#address-cells = < 0x01 >;
				#size-cells = < 0x01 >;
				linux,phandle = < 0x8e >;
				phandle = < 0x8e >;

				baseboard_data@0 {
					reg = < 0x00 0x100 >;
					linux,phandle = < 0x8f >;
					phandle = < 0x8f >;
				};
			};

			tda19988 {
				compatible = "nxp,tda998x";
				reg = < 0x70 >;
				pinctrl-names = "default\0off";
				pinctrl-0 = < 0x2f >;
				pinctrl-1 = < 0x30 >;

				port {

					endpoint@0 {
						remote-endpoint = < 0x31 >;
						linux,phandle = < 0x46 >;
						phandle = < 0x46 >;
					};
				};
			};
		};

		i2c@4802a000 {
			compatible = "ti,omap4-i2c";
			#address-cells = < 0x01 >;
			#size-cells = < 0x00 >;
			ti,hwmods = "i2c2";
			reg = < 0x4802a000 0x1000 >;
			interrupts = < 0x47 >;
			status = "disabled";
			linux,phandle = < 0x90 >;
			phandle = < 0x90 >;
		};

		i2c@4819c000 {
			compatible = "ti,omap4-i2c";
			#address-cells = < 0x01 >;
			#size-cells = < 0x00 >;
			ti,hwmods = "i2c3";
			reg = < 0x4819c000 0x1000 >;
			interrupts = < 0x1e >;
			status = "okay";
			pinctrl-names = "default";
			pinctrl-0 = < 0x32 >;
			clock-frequency = < 0x186a0 >;
			linux,phandle = < 0x91 >;
			phandle = < 0x91 >;

			cape_eeprom0@54 {
				compatible = "at,24c256";
				reg = < 0x54 >;
				#address-cells = < 0x01 >;
				#size-cells = < 0x01 >;
				linux,phandle = < 0x92 >;
				phandle = < 0x92 >;

				cape_data@0 {
					reg = < 0x00 0x100 >;
					linux,phandle = < 0x93 >;
					phandle = < 0x93 >;
				};
			};

			cape_eeprom1@55 {
				compatible = "at,24c256";
				reg = < 0x55 >;
				#address-cells = < 0x01 >;
				#size-cells = < 0x01 >;
				linux,phandle = < 0x94 >;
				phandle = < 0x94 >;

				cape_data@0 {
					reg = < 0x00 0x100 >;
					linux,phandle = < 0x95 >;
					phandle = < 0x95 >;
				};
			};

			cape_eeprom2@56 {
				compatible = "at,24c256";
				reg = < 0x56 >;
				#address-cells = < 0x01 >;
				#size-cells = < 0x01 >;
				linux,phandle = < 0x96 >;
				phandle = < 0x96 >;

				cape_data@0 {
					reg = < 0x00 0x100 >;
					linux,phandle = < 0x97 >;
					phandle = < 0x97 >;
				};
			};

			cape_eeprom3@57 {
				compatible = "at,24c256";
				reg = < 0x57 >;
				#address-cells = < 0x01 >;
				#size-cells = < 0x01 >;
				linux,phandle = < 0x98 >;
				phandle = < 0x98 >;

				cape_data@0 {
					reg = < 0x00 0x100 >;
					linux,phandle = < 0x99 >;
					phandle = < 0x99 >;
				};
			};
		};

		mmc@48060000 {
			compatible = "ti,omap4-hsmmc";
			ti,hwmods = "mmc1";
			ti,dual-volt;
			ti,needs-special-reset;
			ti,needs-special-hs-handling;
			dmas = < 0x33 0x18 0x00 0x00 0x33 0x19 0x00 0x00 >;
			dma-names = "tx\0rx";
			interrupts = < 0x40 >;
			interrupt-parent = < 0x01 >;
			reg = < 0x48060000 0x1000 >;
			status = "okay";
			bus-width = < 0x04 >;
			pinctrl-names = "default";
			pinctrl-0 = < 0x34 >;
			cd-gpios = < 0x35 0x06 0x01 >;
			vmmc-supply = < 0x36 >;
			linux,phandle = < 0x9a >;
			phandle = < 0x9a >;
		};

		mmc@481d8000 {
			compatible = "ti,omap4-hsmmc";
			ti,hwmods = "mmc2";
			ti,needs-special-reset;
			dmas = < 0x29 0x02 0x00 0x29 0x03 0x00 >;
			dma-names = "tx\0rx";
			interrupts = < 0x1c >;
			interrupt-parent = < 0x01 >;
			reg = < 0x481d8000 0x1000 >;
			status = "okay";
			vmmc-supply = < 0x36 >;
			pinctrl-names = "default";
			pinctrl-0 = < 0x37 >;
			bus-width = < 0x08 >;
			linux,phandle = < 0x9b >;
			phandle = < 0x9b >;
		};

		mmc@47810000 {
			compatible = "ti,omap4-hsmmc";
			ti,hwmods = "mmc3";
			ti,needs-special-reset;
			interrupts = < 0x1d >;
			interrupt-parent = < 0x01 >;
			reg = < 0x47810000 0x1000 >;
			status = "disabled";
			linux,phandle = < 0x9c >;
			phandle = < 0x9c >;
		};

		spinlock@480ca000 {
			compatible = "ti,omap4-hwspinlock";
			reg = < 0x480ca000 0x1000 >;
			ti,hwmods = "spinlock";
			#hwlock-cells = < 0x01 >;
			linux,phandle = < 0x9d >;
			phandle = < 0x9d >;
		};

		wdt@44e35000 {
			compatible = "ti,omap3-wdt";
			ti,hwmods = "wd_timer2";
			reg = < 0x44e35000 0x1000 >;
			interrupts = < 0x5b >;
			linux,phandle = < 0x9e >;
			phandle = < 0x9e >;
		};

		can@481cc000 {
			compatible = "ti,am3352-d_can";
			ti,hwmods = "d_can0";
			reg = < 0x481cc000 0x2000 >;
			clocks = < 0x38 >;
			clock-names = "fck";
			syscon-raminit = < 0x39 0x644 0x00 >;
			interrupts = < 0x34 >;
			status = "disabled";
			linux,phandle = < 0x9f >;
			phandle = < 0x9f >;
		};

		can@481d0000 {
			compatible = "ti,am3352-d_can";
			ti,hwmods = "d_can1";
			reg = < 0x481d0000 0x2000 >;
			clocks = < 0x3a >;
			clock-names = "fck";
			syscon-raminit = < 0x39 0x644 0x01 >;
			interrupts = < 0x37 >;
			status = "disabled";
			linux,phandle = < 0xa0 >;
			phandle = < 0xa0 >;
		};

		mailbox@480C8000 {
			compatible = "ti,omap4-mailbox";
			reg = < 0x480c8000 0x200 >;
			interrupts = < 0x4d >;
			ti,hwmods = "mailbox";
			#mbox-cells = < 0x01 >;
			ti,mbox-num-users = < 0x04 >;
			ti,mbox-num-fifos = < 0x08 >;
			linux,phandle = < 0x27 >;
			phandle = < 0x27 >;

			wkup_m3 {
				ti,mbox-send-noirq;
				ti,mbox-tx = < 0x00 0x00 0x00 >;
				ti,mbox-rx = < 0x00 0x00 0x03 >;
				linux,phandle = < 0x28 >;
				phandle = < 0x28 >;
			};
		};

		timer@44e31000 {
			compatible = "ti,am335x-timer-1ms";
			reg = < 0x44e31000 0x400 >;
			interrupts = < 0x43 >;
			ti,hwmods = "timer1";
			ti,timer-alwon;
			linux,phandle = < 0xa1 >;
			phandle = < 0xa1 >;
		};

		timer@48040000 {
			compatible = "ti,am335x-timer";
			reg = < 0x48040000 0x400 >;
			interrupts = < 0x44 >;
			ti,hwmods = "timer2";
			linux,phandle = < 0xa2 >;
			phandle = < 0xa2 >;
		};

		timer@48042000 {
			compatible = "ti,am335x-timer";
			reg = < 0x48042000 0x400 >;
			interrupts = < 0x45 >;
			ti,hwmods = "timer3";
			linux,phandle = < 0xa3 >;
			phandle = < 0xa3 >;
		};

		timer@48044000 {
			compatible = "ti,am335x-timer";
			reg = < 0x48044000 0x400 >;
			interrupts = < 0x5c >;
			ti,hwmods = "timer4";
			ti,timer-pwm;
			linux,phandle = < 0xa4 >;
			phandle = < 0xa4 >;
		};

		timer@48046000 {
			compatible = "ti,am335x-timer";
			reg = < 0x48046000 0x400 >;
			interrupts = < 0x5d >;
			ti,hwmods = "timer5";
			ti,timer-pwm;
			linux,phandle = < 0xa5 >;
			phandle = < 0xa5 >;
		};

		timer@48048000 {
			compatible = "ti,am335x-timer";
			reg = < 0x48048000 0x400 >;
			interrupts = < 0x5e >;
			ti,hwmods = "timer6";
			ti,timer-pwm;
			linux,phandle = < 0xa6 >;
			phandle = < 0xa6 >;
		};

		timer@4804a000 {
			compatible = "ti,am335x-timer";
			reg = < 0x4804a000 0x400 >;
			interrupts = < 0x5f >;
			ti,hwmods = "timer7";
			ti,timer-pwm;
			linux,phandle = < 0xa7 >;
			phandle = < 0xa7 >;
		};

		rtc@44e3e000 {
			compatible = "ti,am3352-rtc\0ti,da830-rtc";
			reg = < 0x44e3e000 0x1000 >;
			interrupts = < 0x4b 0x4c >;
			ti,hwmods = "rtc";
			system-power-controller;
			linux,phandle = < 0xa8 >;
			phandle = < 0xa8 >;
		};

		spi@48030000 {
			compatible = "ti,omap4-mcspi";
			#address-cells = < 0x01 >;
			#size-cells = < 0x00 >;
			reg = < 0x48030000 0x400 >;
			interrupts = < 0x41 >;
			ti,spi-num-cs = < 0x02 >;
			ti,hwmods = "spi0";
			dmas = < 0x29 0x10 0x00 0x29 0x11 0x00 0x29 0x12 0x00 0x29 0x13 0x00 >;
			dma-names = "tx0\0rx0\0tx1\0rx1";
			status = "disabled";
			linux,phandle = < 0xa9 >;
			phandle = < 0xa9 >;
		};

		spi@481a0000 {
			compatible = "ti,omap4-mcspi";
			#address-cells = < 0x01 >;
			#size-cells = < 0x00 >;
			reg = < 0x481a0000 0x400 >;
			interrupts = < 0x7d >;
			ti,spi-num-cs = < 0x02 >;
			ti,hwmods = "spi1";
			dmas = < 0x29 0x2a 0x00 0x29 0x2b 0x00 0x29 0x2c 0x00 0x29 0x2d 0x00 >;
			dma-names = "tx0\0rx0\0tx1\0rx1";
			status = "disabled";
			linux,phandle = < 0xaa >;
			phandle = < 0xaa >;
		};

		usb@47400000 {
			compatible = "ti,am33xx-usb";
			reg = < 0x47400000 0x1000 >;
			ranges;
			#address-cells = < 0x01 >;
			#size-cells = < 0x01 >;
			ti,hwmods = "usb_otg_hs";
			status = "okay";
			linux,phandle = < 0xab >;
			phandle = < 0xab >;

			control@44e10620 {
				compatible = "ti,am335x-usb-ctrl-module";
				reg = < 0x44e10620 0x10 0x44e10648 0x04 >;
				reg-names = "phy_ctrl\0wakeup";
				status = "okay";
				linux,phandle = < 0x3b >;
				phandle = < 0x3b >;
			};

			usb-phy@47401300 {
				compatible = "ti,am335x-usb-phy";
				reg = < 0x47401300 0x100 >;
				reg-names = "phy";
				status = "okay";
				ti,ctrl_mod = < 0x3b >;
				linux,phandle = < 0x3c >;
				phandle = < 0x3c >;
			};

			usb@47401000 {
				compatible = "ti,musb-am33xx";
				status = "okay";
				reg = < 0x47401400 0x400 0x47401000 0x200 >;
				reg-names = "mc\0control";
				interrupts = < 0x12 >;
				interrupt-names = "mc";
				dr_mode = "peripheral";
				mentor,multipoint = < 0x01 >;
				mentor,num-eps = < 0x10 >;
				mentor,ram-bits = < 0x0c >;
				mentor,power = < 0x1f4 >;
				phys = < 0x3c >;
				dmas = < 0x3d 0x00 0x00 0x3d 0x01 0x00 0x3d 0x02 0x00 0x3d 0x03 0x00 0x3d 0x04 0x00 0x3d 0x05 0x00 0x3d 0x06 0x00 0x3d 0x07 0x00 0x3d 0x08 0x00 0x3d 0x09 0x00 0x3d 0x0a 0x00 0x3d 0x0b 0x00 0x3d 0x0c 0x00 0x3d 0x0d 0x00 0x3d 0x0e 0x00 0x3d 0x00 0x01 0x3d 0x01 0x01 0x3d 0x02 0x01 0x3d 0x03 0x01 0x3d 0x04 0x01 0x3d 0x05 0x01 0x3d 0x06 0x01 0x3d 0x07 0x01 0x3d 0x08 0x01 0x3d 0x09 0x01 0x3d 0x0a 0x01 0x3d 0x0b 0x01 0x3d 0x0c 0x01 0x3d 0x0d 0x01 0x3d 0x0e 0x01 >;
				dma-names = "rx1\0rx2\0rx3\0rx4\0rx5\0rx6\0rx7\0rx8\0rx9\0rx10\0rx11\0rx12\0rx13\0rx14\0rx15\0tx1\0tx2\0tx3\0tx4\0tx5\0tx6\0tx7\0tx8\0tx9\0tx10\0tx11\0tx12\0tx13\0tx14\0tx15";
				linux,phandle = < 0xac >;
				phandle = < 0xac >;
			};

			usb-phy@47401b00 {
				compatible = "ti,am335x-usb-phy";
				reg = < 0x47401b00 0x100 >;
				reg-names = "phy";
				status = "okay";
				ti,ctrl_mod = < 0x3b >;
				linux,phandle = < 0x3e >;
				phandle = < 0x3e >;
			};

			usb@47401800 {
				compatible = "ti,musb-am33xx";
				status = "okay";
				reg = < 0x47401c00 0x400 0x47401800 0x200 >;
				reg-names = "mc\0control";
				interrupts = < 0x13 >;
				interrupt-names = "mc";
				dr_mode = "host";
				mentor,multipoint = < 0x01 >;
				mentor,num-eps = < 0x10 >;
				mentor,ram-bits = < 0x0c >;
				mentor,power = < 0x1f4 >;
				phys = < 0x3e >;
				dmas = < 0x3d 0x0f 0x00 0x3d 0x10 0x00 0x3d 0x11 0x00 0x3d 0x12 0x00 0x3d 0x13 0x00 0x3d 0x14 0x00 0x3d 0x15 0x00 0x3d 0x16 0x00 0x3d 0x17 0x00 0x3d 0x18 0x00 0x3d 0x19 0x00 0x3d 0x1a 0x00 0x3d 0x1b 0x00 0x3d 0x1c 0x00 0x3d 0x1d 0x00 0x3d 0x0f 0x01 0x3d 0x10 0x01 0x3d 0x11 0x01 0x3d 0x12 0x01 0x3d 0x13 0x01 0x3d 0x14 0x01 0x3d 0x15 0x01 0x3d 0x16 0x01 0x3d 0x17 0x01 0x3d 0x18 0x01 0x3d 0x19 0x01 0x3d 0x1a 0x01 0x3d 0x1b 0x01 0x3d 0x1c 0x01 0x3d 0x1d 0x01 >;
				dma-names = "rx1\0rx2\0rx3\0rx4\0rx5\0rx6\0rx7\0rx8\0rx9\0rx10\0rx11\0rx12\0rx13\0rx14\0rx15\0tx1\0tx2\0tx3\0tx4\0tx5\0tx6\0tx7\0tx8\0tx9\0tx10\0tx11\0tx12\0tx13\0tx14\0tx15";
				linux,phandle = < 0xad >;
				phandle = < 0xad >;
			};

			dma-controller@47402000 {
				compatible = "ti,am3359-cppi41";
				reg = < 0x47400000 0x1000 0x47402000 0x1000 0x47403000 0x1000 0x47404000 0x4000 >;
				reg-names = "glue\0controller\0scheduler\0queuemgr";
				interrupts = < 0x11 >;
				interrupt-names = "glue";
				#dma-cells = < 0x02 >;
				#dma-channels = < 0x1e >;
				#dma-requests = < 0x100 >;
				status = "okay";
				linux,phandle = < 0x3d >;
				phandle = < 0x3d >;
			};
		};

		epwmss@48300000 {
			compatible = "ti,am33xx-pwmss";
			reg = < 0x48300000 0x10 >;
			ti,hwmods = "epwmss0";
			#address-cells = < 0x01 >;
			#size-cells = < 0x01 >;
			status = "disabled";
			ranges = < 0x48300100 0x48300100 0x80 0x48300180 0x48300180 0x80 0x48300200 0x48300200 0x80 >;
			linux,phandle = < 0xae >;
			phandle = < 0xae >;

			ecap@48300100 {
				compatible = "ti,am33xx-ecap";
				#pwm-cells = < 0x03 >;
				reg = < 0x48300100 0x80 >;
				interrupts = < 0x1f >;
				interrupt-names = "ecap0";
				ti,hwmods = "ecap0";
				status = "disabled";
				linux,phandle = < 0xaf >;
				phandle = < 0xaf >;
			};

			ehrpwm@48300200 {
				compatible = "ti,am33xx-ehrpwm";
				#pwm-cells = < 0x03 >;
				reg = < 0x48300200 0x80 >;
				ti,hwmods = "ehrpwm0";
				status = "disabled";
				linux,phandle = < 0xb0 >;
				phandle = < 0xb0 >;
			};
		};

		epwmss@48302000 {
			compatible = "ti,am33xx-pwmss";
			reg = < 0x48302000 0x10 >;
			ti,hwmods = "epwmss1";
			#address-cells = < 0x01 >;
			#size-cells = < 0x01 >;
			status = "disabled";
			ranges = < 0x48302100 0x48302100 0x80 0x48302180 0x48302180 0x80 0x48302200 0x48302200 0x80 >;
			linux,phandle = < 0xb1 >;
			phandle = < 0xb1 >;

			ecap@48302100 {
				compatible = "ti,am33xx-ecap";
				#pwm-cells = < 0x03 >;
				reg = < 0x48302100 0x80 >;
				interrupts = < 0x2f >;
				interrupt-names = "ecap1";
				ti,hwmods = "ecap1";
				status = "disabled";
				linux,phandle = < 0xb2 >;
				phandle = < 0xb2 >;
			};

			ehrpwm@48302200 {
				compatible = "ti,am33xx-ehrpwm";
				#pwm-cells = < 0x03 >;
				reg = < 0x48302200 0x80 >;
				ti,hwmods = "ehrpwm1";
				status = "disabled";
				linux,phandle = < 0xb3 >;
				phandle = < 0xb3 >;
			};
		};

		epwmss@48304000 {
			compatible = "ti,am33xx-pwmss";
			reg = < 0x48304000 0x10 >;
			ti,hwmods = "epwmss2";
			#address-cells = < 0x01 >;
			#size-cells = < 0x01 >;
			status = "disabled";
			ranges = < 0x48304100 0x48304100 0x80 0x48304180 0x48304180 0x80 0x48304200 0x48304200 0x80 >;
			linux,phandle = < 0xb4 >;
			phandle = < 0xb4 >;

			ecap@48304100 {
				compatible = "ti,am33xx-ecap";
				#pwm-cells = < 0x03 >;
				reg = < 0x48304100 0x80 >;
				interrupts = < 0x3d >;
				interrupt-names = "ecap2";
				ti,hwmods = "ecap2";
				status = "disabled";
				linux,phandle = < 0xb5 >;
				phandle = < 0xb5 >;
			};

			ehrpwm@48304200 {
				compatible = "ti,am33xx-ehrpwm";
				#pwm-cells = < 0x03 >;
				reg = < 0x48304200 0x80 >;
				ti,hwmods = "ehrpwm2";
				status = "disabled";
				linux,phandle = < 0xb6 >;
				phandle = < 0xb6 >;
			};
		};

		ethernet@4a100000 {
			compatible = "ti,am335x-cpsw\0ti,cpsw";
			ti,hwmods = "cpgmac0";
			clocks = < 0x3f 0x40 >;
			clock-names = "fck\0cpts";
			cpdma_channels = < 0x08 >;
			ale_entries = < 0x400 >;
			bd_ram_size = < 0x2000 >;
			no_bd_ram = < 0x00 >;
			rx_descs = < 0x40 >;
			mac_control = < 0x20 >;
			slaves = < 0x02 >;
			active_slave = < 0x00 >;
			cpts_clock_mult = < 0x80000000 >;
			cpts_clock_shift = < 0x1d >;
			reg = < 0x4a100000 0x800 0x4a101200 0x100 >;
			#address-cells = < 0x01 >;
			#size-cells = < 0x01 >;
			interrupt-parent = < 0x01 >;
			interrupts = < 0x28 0x29 0x2a 0x2b >;
			ranges;
			syscon = < 0x39 >;
			status = "okay";
			pinctrl-names = "default\0sleep";
			pinctrl-0 = < 0x41 >;
			pinctrl-1 = < 0x42 >;
			linux,phandle = < 0xb7 >;
			phandle = < 0xb7 >;

			mdio@4a101000 {
				compatible = "ti,davinci_mdio";
				#address-cells = < 0x01 >;
				#size-cells = < 0x00 >;
				ti,hwmods = "davinci_mdio";
				bus_freq = < 0xf4240 >;
				reg = < 0x4a101000 0x100 >;
				status = "okay";
				pinctrl-names = "default\0sleep";
				pinctrl-0 = < 0x43 >;
				pinctrl-1 = < 0x44 >;
				linux,phandle = < 0x45 >;
				phandle = < 0x45 >;
			};

			slave@4a100200 {
				mac-address = [ 00 00 00 00 00 00 ];
				phy_id = < 0x45 0x00 >;
				phy-mode = "mii";
				linux,phandle = < 0xb8 >;
				phandle = < 0xb8 >;
			};

			slave@4a100300 {
				mac-address = [ 00 00 00 00 00 00 ];
				phy_id = < 0x45 0x01 >;
				phy-mode = "mii";
				linux,phandle = < 0xb9 >;
				phandle = < 0xb9 >;
			};

			cpsw-phy-sel@44e10650 {
				compatible = "ti,am3352-cpsw-phy-sel";
				reg = < 0x44e10650 0x04 >;
				reg-names = "gmii-sel";
				linux,phandle = < 0xba >;
				phandle = < 0xba >;
			};
		};

		ocmcram@40300000 {
			compatible = "mmio-sram";
			reg = < 0x40300000 0x10000 >;
			linux,phandle = < 0xbb >;
			phandle = < 0xbb >;
		};

		elm@48080000 {
			compatible = "ti,am3352-elm";
			reg = < 0x48080000 0x2000 >;
			interrupts = < 0x04 >;
			ti,hwmods = "elm";
			status = "disabled";
			linux,phandle = < 0xbc >;
			phandle = < 0xbc >;
		};

		lcdc@4830e000 {
			compatible = "ti,am33xx-tilcdc";
			reg = < 0x4830e000 0x1000 >;
			interrupt-parent = < 0x01 >;
			interrupts = < 0x24 >;
			ti,hwmods = "lcdc";
			status = "okay";
			linux,phandle = < 0xbd >;
			phandle = < 0xbd >;

			port {

				endpoint@0 {
					remote-endpoint = < 0x46 >;
					linux,phandle = < 0x31 >;
					phandle = < 0x31 >;
				};
			};
		};

		tscadc@44e0d000 {
			compatible = "ti,am3359-tscadc";
			reg = < 0x44e0d000 0x1000 >;
			interrupt-parent = < 0x01 >;
			interrupts = < 0x10 >;
			ti,hwmods = "adc_tsc";
			status = "disabled";
			linux,phandle = < 0xbe >;
			phandle = < 0xbe >;

			tsc {
				compatible = "ti,am3359-tsc";
			};

			adc {
				#io-channel-cells = < 0x01 >;
				compatible = "ti,am3359-adc";
				linux,phandle = < 0xbf >;
				phandle = < 0xbf >;
			};
		};

		gpmc@50000000 {
			compatible = "ti,am3352-gpmc";
			ti,hwmods = "gpmc";
			ti,no-idle-on-init;
			reg = < 0x50000000 0x2000 >;
			interrupts = < 0x64 >;
			dmas = < 0x29 0x34 >;
			dma-names = "rxtx";
			gpmc,num-cs = < 0x07 >;
			gpmc,num-waitpins = < 0x02 >;
			#address-cells = < 0x02 >;
			#size-cells = < 0x01 >;
			status = "disabled";
			linux,phandle = < 0xc0 >;
			phandle = < 0xc0 >;
		};

		sham@53100000 {
			compatible = "ti,omap4-sham";
			ti,hwmods = "sham";
			reg = < 0x53100000 0x200 >;
			interrupts = < 0x6d >;
			dmas = < 0x29 0x24 0x00 >;
			dma-names = "rx";
			status = "okay";
			linux,phandle = < 0xc1 >;
			phandle = < 0xc1 >;
		};

		aes@53500000 {
			compatible = "ti,omap4-aes";
			ti,hwmods = "aes";
			reg = < 0x53500000 0xa0 >;
			interrupts = < 0x67 >;
			dmas = < 0x29 0x06 0x00 0x29 0x05 0x00 >;
			dma-names = "tx\0rx";
			status = "okay";
			linux,phandle = < 0xc2 >;
			phandle = < 0xc2 >;
		};

		mcasp@48038000 {
			compatible = "ti,am33xx-mcasp-audio";
			ti,hwmods = "mcasp0";
			reg = < 0x48038000 0x2000 0x46000000 0x400000 >;
			reg-names = "mpu\0dat";
			interrupts = < 0x50 0x51 >;
			interrupt-names = "tx\0rx";
			status = "disabled";
			dmas = < 0x29 0x08 0x02 0x29 0x09 0x02 >;
			dma-names = "tx\0rx";
			linux,phandle = < 0xc3 >;
			phandle = < 0xc3 >;
		};

		mcasp@4803C000 {
			compatible = "ti,am33xx-mcasp-audio";
			ti,hwmods = "mcasp1";
			reg = < 0x4803c000 0x2000 0x46400000 0x400000 >;
			reg-names = "mpu\0dat";
			interrupts = < 0x52 0x53 >;
			interrupt-names = "tx\0rx";
			status = "disabled";
			dmas = < 0x29 0x0a 0x02 0x29 0x0b 0x02 >;
			dma-names = "tx\0rx";
			linux,phandle = < 0xc4 >;
			phandle = < 0xc4 >;
		};

		rng@48310000 {
			compatible = "ti,omap4-rng";
			ti,hwmods = "rng";
			reg = < 0x48310000 0x2000 >;
			interrupts = < 0x6f >;
			linux,phandle = < 0xc5 >;
			phandle = < 0xc5 >;
		};
	};

	leds {
		pinctrl-names = "default";
		pinctrl-0 = < 0x47 >;
		compatible = "gpio-leds";

		led@2 {
			label = "beaglebone:green:heartbeat";
			gpios = < 0x48 0x15 0x00 >;
			linux,default-trigger = "heartbeat";
			default-state = "off";
		};

		led@3 {
			label = "beaglebone:green:mmc0";
			gpios = < 0x48 0x16 0x00 >;
			linux,default-trigger = "mmc0";
			default-state = "off";
		};

		led@4 {
			label = "beaglebone:green:usr2";
			gpios = < 0x48 0x17 0x00 >;
			linux,default-trigger = "cpu0";
			default-state = "off";
		};

		led@5 {
			label = "beaglebone:green:usr3";
			gpios = < 0x48 0x18 0x00 >;
			linux,default-trigger = "mmc1";
			default-state = "off";
		};
	};

	fixedregulator@0 {
		compatible = "regulator-fixed";
		regulator-name = "vmmcsd_fixed";
		regulator-min-microvolt = < 0x325aa0 >;
		regulator-max-microvolt = < 0x325aa0 >;
		linux,phandle = < 0x36 >;
		phandle = < 0x36 >;
	};

	__symbols__ {
		l4_wkup = "/ocp/l4_wkup@44c00000";
		wkup_m3 = "/ocp/l4_wkup@44c00000/wkup_m3@100000";
		prcm = "/ocp/l4_wkup@44c00000/prcm@200000";
		prcm_clocks = "/ocp/l4_wkup@44c00000/prcm@200000/clocks";
		clk_32768_ck = "/ocp/l4_wkup@44c00000/prcm@200000/clocks/clk_32768_ck";
		clk_rc32k_ck = "/ocp/l4_wkup@44c00000/prcm@200000/clocks/clk_rc32k_ck";
		virt_19200000_ck = "/ocp/l4_wkup@44c00000/prcm@200000/clocks/virt_19200000_ck";
		virt_24000000_ck = "/ocp/l4_wkup@44c00000/prcm@200000/clocks/virt_24000000_ck";
		virt_25000000_ck = "/ocp/l4_wkup@44c00000/prcm@200000/clocks/virt_25000000_ck";
		virt_26000000_ck = "/ocp/l4_wkup@44c00000/prcm@200000/clocks/virt_26000000_ck";
		tclkin_ck = "/ocp/l4_wkup@44c00000/prcm@200000/clocks/tclkin_ck";
		dpll_core_ck = "/ocp/l4_wkup@44c00000/prcm@200000/clocks/dpll_core_ck";
		dpll_core_x2_ck = "/ocp/l4_wkup@44c00000/prcm@200000/clocks/dpll_core_x2_ck";
		dpll_core_m4_ck = "/ocp/l4_wkup@44c00000/prcm@200000/clocks/dpll_core_m4_ck";
		dpll_core_m5_ck = "/ocp/l4_wkup@44c00000/prcm@200000/clocks/dpll_core_m5_ck";
		dpll_core_m6_ck = "/ocp/l4_wkup@44c00000/prcm@200000/clocks/dpll_core_m6_ck";
		dpll_mpu_ck = "/ocp/l4_wkup@44c00000/prcm@200000/clocks/dpll_mpu_ck";
		dpll_mpu_m2_ck = "/ocp/l4_wkup@44c00000/prcm@200000/clocks/dpll_mpu_m2_ck";
		dpll_ddr_ck = "/ocp/l4_wkup@44c00000/prcm@200000/clocks/dpll_ddr_ck";
		dpll_ddr_m2_ck = "/ocp/l4_wkup@44c00000/prcm@200000/clocks/dpll_ddr_m2_ck";
		dpll_ddr_m2_div2_ck = "/ocp/l4_wkup@44c00000/prcm@200000/clocks/dpll_ddr_m2_div2_ck";
		dpll_disp_ck = "/ocp/l4_wkup@44c00000/prcm@200000/clocks/dpll_disp_ck";
		dpll_disp_m2_ck = "/ocp/l4_wkup@44c00000/prcm@200000/clocks/dpll_disp_m2_ck";
		dpll_per_ck = "/ocp/l4_wkup@44c00000/prcm@200000/clocks/dpll_per_ck";
		dpll_per_m2_ck = "/ocp/l4_wkup@44c00000/prcm@200000/clocks/dpll_per_m2_ck";
		dpll_per_m2_div4_wkupdm_ck = "/ocp/l4_wkup@44c00000/prcm@200000/clocks/dpll_per_m2_div4_wkupdm_ck";
		dpll_per_m2_div4_ck = "/ocp/l4_wkup@44c00000/prcm@200000/clocks/dpll_per_m2_div4_ck";
		cefuse_fck = "/ocp/l4_wkup@44c00000/prcm@200000/clocks/cefuse_fck";
		clk_24mhz = "/ocp/l4_wkup@44c00000/prcm@200000/clocks/clk_24mhz";
		clkdiv32k_ck = "/ocp/l4_wkup@44c00000/prcm@200000/clocks/clkdiv32k_ck";
		clkdiv32k_ick = "/ocp/l4_wkup@44c00000/prcm@200000/clocks/clkdiv32k_ick";
		l3_gclk = "/ocp/l4_wkup@44c00000/prcm@200000/clocks/l3_gclk";
		pruss_ocp_gclk = "/ocp/l4_wkup@44c00000/prcm@200000/clocks/pruss_ocp_gclk";
		mmu_fck = "/ocp/l4_wkup@44c00000/prcm@200000/clocks/mmu_fck";
		timer1_fck = "/ocp/l4_wkup@44c00000/prcm@200000/clocks/timer1_fck";
		timer2_fck = "/ocp/l4_wkup@44c00000/prcm@200000/clocks/timer2_fck";
		timer3_fck = "/ocp/l4_wkup@44c00000/prcm@200000/clocks/timer3_fck";
		timer4_fck = "/ocp/l4_wkup@44c00000/prcm@200000/clocks/timer4_fck";
		timer5_fck = "/ocp/l4_wkup@44c00000/prcm@200000/clocks/timer5_fck";
		timer6_fck = "/ocp/l4_wkup@44c00000/prcm@200000/clocks/timer6_fck";
		timer7_fck = "/ocp/l4_wkup@44c00000/prcm@200000/clocks/timer7_fck";
		usbotg_fck = "/ocp/l4_wkup@44c00000/prcm@200000/clocks/usbotg_fck";
		dpll_core_m4_div2_ck = "/ocp/l4_wkup@44c00000/prcm@200000/clocks/dpll_core_m4_div2_ck";
		ieee5000_fck = "/ocp/l4_wkup@44c00000/prcm@200000/clocks/ieee5000_fck";
		wdt1_fck = "/ocp/l4_wkup@44c00000/prcm@200000/clocks/wdt1_fck";
		l4_rtc_gclk = "/ocp/l4_wkup@44c00000/prcm@200000/clocks/l4_rtc_gclk";
		l4hs_gclk = "/ocp/l4_wkup@44c00000/prcm@200000/clocks/l4hs_gclk";
		l3s_gclk = "/ocp/l4_wkup@44c00000/prcm@200000/clocks/l3s_gclk";
		l4fw_gclk = "/ocp/l4_wkup@44c00000/prcm@200000/clocks/l4fw_gclk";
		l4ls_gclk = "/ocp/l4_wkup@44c00000/prcm@200000/clocks/l4ls_gclk";
		sysclk_div_ck = "/ocp/l4_wkup@44c00000/prcm@200000/clocks/sysclk_div_ck";
		cpsw_125mhz_gclk = "/ocp/l4_wkup@44c00000/prcm@200000/clocks/cpsw_125mhz_gclk";
		cpsw_cpts_rft_clk = "/ocp/l4_wkup@44c00000/prcm@200000/clocks/cpsw_cpts_rft_clk";
		gpio0_dbclk_mux_ck = "/ocp/l4_wkup@44c00000/prcm@200000/clocks/gpio0_dbclk_mux_ck";
		gpio0_dbclk = "/ocp/l4_wkup@44c00000/prcm@200000/clocks/gpio0_dbclk";
		gpio1_dbclk = "/ocp/l4_wkup@44c00000/prcm@200000/clocks/gpio1_dbclk";
		gpio2_dbclk = "/ocp/l4_wkup@44c00000/prcm@200000/clocks/gpio2_dbclk";
		gpio3_dbclk = "/ocp/l4_wkup@44c00000/prcm@200000/clocks/gpio3_dbclk";
		lcd_gclk = "/ocp/l4_wkup@44c00000/prcm@200000/clocks/lcd_gclk";
		mmc_clk = "/ocp/l4_wkup@44c00000/prcm@200000/clocks/mmc_clk";
		gfx_fclk_clksel_ck = "/ocp/l4_wkup@44c00000/prcm@200000/clocks/gfx_fclk_clksel_ck";
		gfx_fck_div_ck = "/ocp/l4_wkup@44c00000/prcm@200000/clocks/gfx_fck_div_ck";
		sysclkout_pre_ck = "/ocp/l4_wkup@44c00000/prcm@200000/clocks/sysclkout_pre_ck";
		clkout2_div_ck = "/ocp/l4_wkup@44c00000/prcm@200000/clocks/clkout2_div_ck";
		dbg_sysclk_ck = "/ocp/l4_wkup@44c00000/prcm@200000/clocks/dbg_sysclk_ck";
		dbg_clka_ck = "/ocp/l4_wkup@44c00000/prcm@200000/clocks/dbg_clka_ck";
		stm_pmd_clock_mux_ck = "/ocp/l4_wkup@44c00000/prcm@200000/clocks/stm_pmd_clock_mux_ck";
		trace_pmd_clk_mux_ck = "/ocp/l4_wkup@44c00000/prcm@200000/clocks/trace_pmd_clk_mux_ck";
		stm_clk_div_ck = "/ocp/l4_wkup@44c00000/prcm@200000/clocks/stm_clk_div_ck";
		trace_clk_div_ck = "/ocp/l4_wkup@44c00000/prcm@200000/clocks/trace_clk_div_ck";
		clkout2_ck = "/ocp/l4_wkup@44c00000/prcm@200000/clocks/clkout2_ck";
		prcm_clockdomains = "/ocp/l4_wkup@44c00000/prcm@200000/clockdomains";
		clk_24mhz_clkdm = "/ocp/l4_wkup@44c00000/prcm@200000/clockdomains/clk_24mhz_clkdm";
		scm = "/ocp/l4_wkup@44c00000/scm@210000";
		am33xx_pinmux = "/ocp/l4_wkup@44c00000/scm@210000/pinmux@800";
		user_leds_s0 = "/ocp/l4_wkup@44c00000/scm@210000/pinmux@800/user_leds_s0";
		i2c0_pins = "/ocp/l4_wkup@44c00000/scm@210000/pinmux@800/pinmux_i2c0_pins";
		i2c2_pins = "/ocp/l4_wkup@44c00000/scm@210000/pinmux@800/pinmux_i2c2_pins";
		uart0_pins = "/ocp/l4_wkup@44c00000/scm@210000/pinmux@800/pinmux_uart0_pins";
		clkout2_pin = "/ocp/l4_wkup@44c00000/scm@210000/pinmux@800/pinmux_clkout2_pin";
		cpsw_default = "/ocp/l4_wkup@44c00000/scm@210000/pinmux@800/cpsw_default";
		cpsw_sleep = "/ocp/l4_wkup@44c00000/scm@210000/pinmux@800/cpsw_sleep";
		davinci_mdio_default = "/ocp/l4_wkup@44c00000/scm@210000/pinmux@800/davinci_mdio_default";
		davinci_mdio_sleep = "/ocp/l4_wkup@44c00000/scm@210000/pinmux@800/davinci_mdio_sleep";
		mmc1_pins = "/ocp/l4_wkup@44c00000/scm@210000/pinmux@800/pinmux_mmc1_pins";
		emmc_pins = "/ocp/l4_wkup@44c00000/scm@210000/pinmux@800/pinmux_emmc_pins";
		nxp_hdmi_bonelt_pins = "/ocp/l4_wkup@44c00000/scm@210000/pinmux@800/nxp_hdmi_bonelt_pins";
		nxp_hdmi_bonelt_off_pins = "/ocp/l4_wkup@44c00000/scm@210000/pinmux@800/nxp_hdmi_bonelt_off_pins";
		scm_conf = "/ocp/l4_wkup@44c00000/scm@210000/scm_conf@0";
		scm_clocks = "/ocp/l4_wkup@44c00000/scm@210000/scm_conf@0/clocks";
		sys_clkin_ck = "/ocp/l4_wkup@44c00000/scm@210000/scm_conf@0/clocks/sys_clkin_ck";
		adc_tsc_fck = "/ocp/l4_wkup@44c00000/scm@210000/scm_conf@0/clocks/adc_tsc_fck";
		dcan0_fck = "/ocp/l4_wkup@44c00000/scm@210000/scm_conf@0/clocks/dcan0_fck";
		dcan1_fck = "/ocp/l4_wkup@44c00000/scm@210000/scm_conf@0/clocks/dcan1_fck";
		mcasp0_fck = "/ocp/l4_wkup@44c00000/scm@210000/scm_conf@0/clocks/mcasp0_fck";
		mcasp1_fck = "/ocp/l4_wkup@44c00000/scm@210000/scm_conf@0/clocks/mcasp1_fck";
		smartreflex0_fck = "/ocp/l4_wkup@44c00000/scm@210000/scm_conf@0/clocks/smartreflex0_fck";
		smartreflex1_fck = "/ocp/l4_wkup@44c00000/scm@210000/scm_conf@0/clocks/smartreflex1_fck";
		sha0_fck = "/ocp/l4_wkup@44c00000/scm@210000/scm_conf@0/clocks/sha0_fck";
		aes0_fck = "/ocp/l4_wkup@44c00000/scm@210000/scm_conf@0/clocks/aes0_fck";
		rng_fck = "/ocp/l4_wkup@44c00000/scm@210000/scm_conf@0/clocks/rng_fck";
		ehrpwm0_tbclk = "/ocp/l4_wkup@44c00000/scm@210000/scm_conf@0/clocks/ehrpwm0_tbclk@44e10664";
		ehrpwm1_tbclk = "/ocp/l4_wkup@44c00000/scm@210000/scm_conf@0/clocks/ehrpwm1_tbclk@44e10664";
		ehrpwm2_tbclk = "/ocp/l4_wkup@44c00000/scm@210000/scm_conf@0/clocks/ehrpwm2_tbclk@44e10664";
		wkup_m3_ipc = "/ocp/l4_wkup@44c00000/scm@210000/wkup_m3_ipc@1324";
		edma_xbar = "/ocp/l4_wkup@44c00000/scm@210000/dma-router@f90";
		scm_clockdomains = "/ocp/l4_wkup@44c00000/scm@210000/clockdomains";
		intc = "/ocp/interrupt-controller@48200000";
		edma = "/ocp/edma@49000000";
		edma_tptc0 = "/ocp/tptc@49800000";
		edma_tptc1 = "/ocp/tptc@49900000";
		edma_tptc2 = "/ocp/tptc@49a00000";
		gpio0 = "/ocp/gpio@44e07000";
		gpio1 = "/ocp/gpio@4804c000";
		gpio2 = "/ocp/gpio@481ac000";
		gpio3 = "/ocp/gpio@481ae000";
		uart0 = "/ocp/serial@44e09000";
		uart1 = "/ocp/serial@48022000";
		uart2 = "/ocp/serial@48024000";
		uart3 = "/ocp/serial@481a6000";
		uart4 = "/ocp/serial@481a8000";
		uart5 = "/ocp/serial@481aa000";
		i2c0 = "/ocp/i2c@44e0b000";
		tps = "/ocp/i2c@44e0b000/tps@24";
		dcdc1_reg = "/ocp/i2c@44e0b000/tps@24/regulators/regulator@0";
		dcdc2_reg = "/ocp/i2c@44e0b000/tps@24/regulators/regulator@1";
		dcdc3_reg = "/ocp/i2c@44e0b000/tps@24/regulators/regulator@2";
		ldo1_reg = "/ocp/i2c@44e0b000/tps@24/regulators/regulator@3";
		ldo2_reg = "/ocp/i2c@44e0b000/tps@24/regulators/regulator@4";
		ldo3_reg = "/ocp/i2c@44e0b000/tps@24/regulators/regulator@5";
		ldo4_reg = "/ocp/i2c@44e0b000/tps@24/regulators/regulator@6";
		baseboard_eeprom = "/ocp/i2c@44e0b000/baseboard_eeprom@50";
		baseboard_data = "/ocp/i2c@44e0b000/baseboard_eeprom@50/baseboard_data@0";
		hdmi_0 = "/ocp/i2c@44e0b000/tda19988/port/endpoint@0";
		i2c1 = "/ocp/i2c@4802a000";
		i2c2 = "/ocp/i2c@4819c000";
		cape_eeprom0 = "/ocp/i2c@4819c000/cape_eeprom0@54";
		cape0_data = "/ocp/i2c@4819c000/cape_eeprom0@54/cape_data@0";
		cape_eeprom1 = "/ocp/i2c@4819c000/cape_eeprom1@55";
		cape1_data = "/ocp/i2c@4819c000/cape_eeprom1@55/cape_data@0";
		cape_eeprom2 = "/ocp/i2c@4819c000/cape_eeprom2@56";
		cape2_data = "/ocp/i2c@4819c000/cape_eeprom2@56/cape_data@0";
		cape_eeprom3 = "/ocp/i2c@4819c000/cape_eeprom3@57";
		cape3_data = "/ocp/i2c@4819c000/cape_eeprom3@57/cape_data@0";
		mmc1 = "/ocp/mmc@48060000";
		mmc2 = "/ocp/mmc@481d8000";
		mmc3 = "/ocp/mmc@47810000";
		hwspinlock = "/ocp/spinlock@480ca000";
		wdt2 = "/ocp/wdt@44e35000";
		dcan0 = "/ocp/can@481cc000";
		dcan1 = "/ocp/can@481d0000";
		mailbox = "/ocp/mailbox@480C8000";
		mbox_wkupm3 = "/ocp/mailbox@480C8000/wkup_m3";
		timer1 = "/ocp/timer@44e31000";
		timer2 = "/ocp/timer@48040000";
		timer3 = "/ocp/timer@48042000";
		timer4 = "/ocp/timer@48044000";
		timer5 = "/ocp/timer@48046000";
		timer6 = "/ocp/timer@48048000";
		timer7 = "/ocp/timer@4804a000";
		rtc = "/ocp/rtc@44e3e000";
		spi0 = "/ocp/spi@48030000";
		spi1 = "/ocp/spi@481a0000";
		usb = "/ocp/usb@47400000";
		usb_ctrl_mod = "/ocp/usb@47400000/control@44e10620";
		usb0_phy = "/ocp/usb@47400000/usb-phy@47401300";
		usb0 = "/ocp/usb@47400000/usb@47401000";
		usb1_phy = "/ocp/usb@47400000/usb-phy@47401b00";
		usb1 = "/ocp/usb@47400000/usb@47401800";
		cppi41dma = "/ocp/usb@47400000/dma-controller@47402000";
		epwmss0 = "/ocp/epwmss@48300000";
		ecap0 = "/ocp/epwmss@48300000/ecap@48300100";
		ehrpwm0 = "/ocp/epwmss@48300000/ehrpwm@48300200";
		epwmss1 = "/ocp/epwmss@48302000";
		ecap1 = "/ocp/epwmss@48302000/ecap@48302100";
		ehrpwm1 = "/ocp/epwmss@48302000/ehrpwm@48302200";
		epwmss2 = "/ocp/epwmss@48304000";
		ecap2 = "/ocp/epwmss@48304000/ecap@48304100";
		ehrpwm2 = "/ocp/epwmss@48304000/ehrpwm@48304200";
		mac = "/ocp/ethernet@4a100000";
		davinci_mdio = "/ocp/ethernet@4a100000/mdio@4a101000";
		cpsw_emac0 = "/ocp/ethernet@4a100000/slave@4a100200";
		cpsw_emac1 = "/ocp/ethernet@4a100000/slave@4a100300";
		phy_sel = "/ocp/ethernet@4a100000/cpsw-phy-sel@44e10650";
		ocmcram = "/ocp/ocmcram@40300000";
		elm = "/ocp/elm@48080000";
		lcdc = "/ocp/lcdc@4830e000";
		lcdc_0 = "/ocp/lcdc@4830e000/port/endpoint@0";
		tscadc = "/ocp/tscadc@44e0d000";
		am335x_adc = "/ocp/tscadc@44e0d000/adc";
		gpmc = "/ocp/gpmc@50000000";
		sham = "/ocp/sham@53100000";
		aes = "/ocp/aes@53500000";
		mcasp0 = "/ocp/mcasp@48038000";
		mcasp1 = "/ocp/mcasp@4803C000";
		rng = "/ocp/rng@48310000";
		vmmcsd_fixed = "/fixedregulator@0";
	};
};
